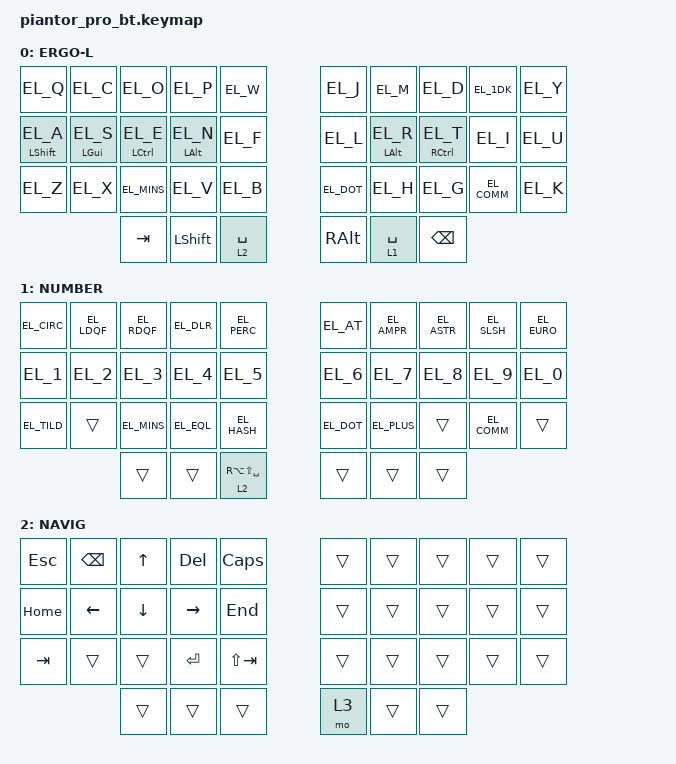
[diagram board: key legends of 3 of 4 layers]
/*
 * Copyright (c) 2020 The ZMK Contributors
 *
 * SPDX-License-Identifier: MIT
 */

#include <behaviors.dtsi>
#include <dt-bindings/zmk/keys.h>
#include <dt-bindings/zmk/bt.h>

#include "keymap_ergol.h"

#define xxx &none
#define ___ &trans 

/ {
    chosen {
        zmk,physical-layout = &five_col_layout;
    };
};

/ {
    behaviors {
        hm: homerow_mods {
            compatible = "zmk,behavior-hold-tap";
            label = "HOMEROW_MODS";
            #binding-cells = <2>;
            tapping-term-ms = <300>; 
            quick-tap-ms = <0>;
            flavor = "balanced";
            bindings = <&kp>, <&kp>;
        };
    };
};

/ {
    keymap {
        compatible = "zmk,keymap";

        default_layer {
            display-name = "ERGO-L";
            // -------------------------------------------------------------------------
            // |  Q  |  C  |  O  |  P  |  W  |           |  J  |  M  |  D  | 1dk |  Y  |
            // |  A  |  S  |  E  |  N  |  F  |           |  L  |  R  |  T  |  I  |  U  |
            // |  Z  |  X  |  -  |  V  |  B  |           |  .  |  H  |  G  |  ,  |  K  |
            //                   | TAB | SFT | NAV | ALG | NUM | BCK |
            bindings = <
&kp EL_Q        &kp EL_C       &kp EL_O        &kp EL_P       &kp EL_W                          &kp EL_J     &kp EL_M       &kp EL_D        &kp EL_1DK   &kp EL_Y
&hm LSHFT EL_A  &hm LGUI EL_S  &hm LCTRL EL_E  &hm LALT EL_N  &kp EL_F                          &kp EL_L     &hm LALT EL_R  &hm RCTRL EL_T  &kp EL_I     &kp EL_U
&kp EL_Z        &kp EL_X       &kp EL_MINS     &kp EL_V       &kp EL_B                          &kp EL_DOT   &kp EL_H       &kp EL_G        &kp EL_COMM  &kp EL_K
                                               &kp TAB        &kp LSHFT  &lt 2 SPACE  &kp RALT  &lt 1 SPACE  &kp BSPC
            >;
        };

        num_layer {
            display-name = "NUMBER";
            // -------------------------------------------------------------------------
            // |  ^  |  «  |  »  |  $  |  %  |           |  @  |  &  |  *  |  /  |  €  |
            // |  1  |  2  |  3  |  4  |  5  |           |  6  |  7  |  8  |  9  |  0  |
            // |  ~  |     |  -  |  =  |  #  |           |  .  |  +  |     |  ,  |     |
            //                   |     |     | NAV | -X- |     |     |     
            bindings = <
&kp EL_CIRC  &kp EL_LDQF  &kp EL_RDQF  &kp EL_DLR  &kp EL_PERC                            &kp EL_AT   &kp EL_AMPR  &kp EL_ASTR  &kp EL_SLSH  &kp EL_EURO
&kp EL_1     &kp EL_2     &kp EL_3     &kp EL_4    &kp EL_5                               &kp EL_6    &kp EL_7     &kp EL_8     &kp EL_9     &kp EL_0
&kp EL_TILD  ___          &kp EL_MINS  &kp EL_EQL  &kp EL_HASH                            &kp EL_DOT  &kp EL_PLUS  ___          &kp EL_COMM  ___
                                       ___         ___          &lt 2 RA(LS(SPACE))  ___  ___         ___
            >;
        };

        nav_layer {
            display-name = "NAVIG";
            // -------------------------------------------------------------------------
            // | ESC | BCK |  ^  | DEL | CPL |           |     |     |     |     |     |
            // | HOM |  <- |  v  | ->  | END |           |     |     |     |     |     |
            // | TAB |     |     | RET | STB |           |     |     |     |     |     |
            //                   |     |     | -X- | CNF |     |     |       
            bindings = <
&kp ESC   &kp BSPC  &kp UP    &kp DEL    &kp CAPS          ___    ___  ___  ___  ___
&kp HOME  &kp LEFT  &kp DOWN  &kp RIGHT  &kp END           ___    ___  ___  ___  ___
&kp TAB   ___       ___       &kp RET    &kp LS(TAB)       ___    ___  ___  ___  ___
                              ___        ___          ___  &mo 3  ___  ___       
            >;
        };

        conf_layer {
            display-name = "CONFIG";
            // -------------------------------------------------------------------------
            // |     |     |     |     |     |           |     |     |     |     |     |
            // | BT1 | BT2 | BT3 | BT4 | BT5 |           | RST | BTL |     |     | BTC |
            // |     |     |     |     |     |           |     |     |     |     |     |
            //                   |     |     |     | -X- |     |     |
            bindings = <
___           ___           ___           ___           ___                     ___         ___          ___  ___  ___
&bt BT_SEL 0  &bt BT_SEL 1  &bt BT_SEL 2  &bt BT_SEL 3  &bt BT_SEL 4            &sys_reset  &bootloader  ___  ___  &bt BT_CLR
___           ___           ___           ___           ___           ___  ___  ___         ___          ___  ___  ___
                                          ___           ___           ___  ___  ___         ___ 
            >;
        };

    };
};
